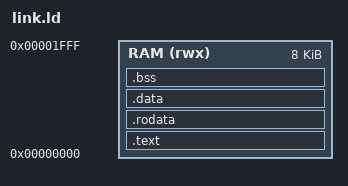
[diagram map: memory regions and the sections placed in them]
/* link.ld - 8 KB RAM, stack at the top */
OUTPUT_ARCH(riscv)
ENTRY(_start)

MEMORY
{
    RAM (rwx) : ORIGIN = 0x00000000, LENGTH = 8K
}

SECTIONS
{
    .text : {
        KEEP(*(.text.start))
        *(.text .text.*)
    } > RAM
    .rodata : ALIGN(4) {
        *(.rodata .rodata.* .srodata .srodata.*)
    } > RAM
    /* must stay empty: a restart does not reload the image */
    .data : ALIGN(4) {
        *(.data .data.* .sdata .sdata.*)
    } > RAM
    .bss (NOLOAD) : ALIGN(4) {
        __bss_start = .;
        *(.bss .bss.* .sbss .sbss.* COMMON)
        . = ALIGN(4);
        __bss_end = .;
    } > RAM
    __global_pointer$ = __bss_start + 0x800;
    __stack_top = ORIGIN(RAM) + LENGTH(RAM);
    /DISCARD/ : { *(.comment) *(.note .note.*) *(.eh_frame .eh_frame_hdr) }
}

ASSERT(SIZEOF(.data) == 0, "pqse_card: initialized writable data (.data): make it const, or set it in code")
/* stack size is checked in the Makefile after linking */
